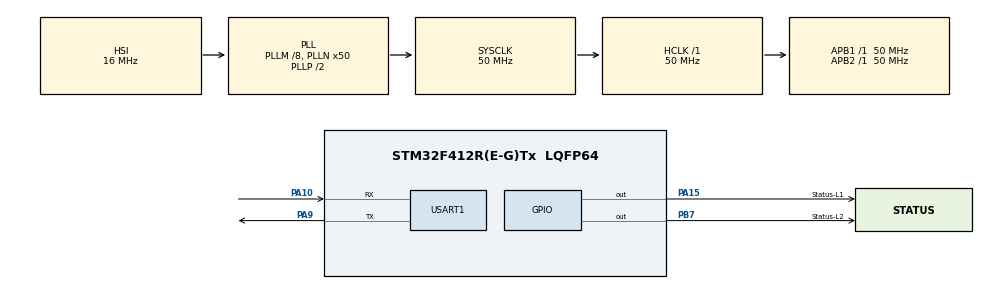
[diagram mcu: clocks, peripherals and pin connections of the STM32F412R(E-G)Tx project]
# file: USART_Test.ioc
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Mcu.Family=STM32F4
Mcu.Name=STM32F412R(E-G)Tx
Mcu.Package=LQFP64
NVIC.PriorityGroup=NVIC_PRIORITYGROUP_4
PA10.Mode=Asynchronous
PA10.Signal=USART1_RX
PA13.Mode=Serial_Wire
PA13.Signal=SYS_JTMS-SWDIO
PA14.Mode=Serial_Wire
PA14.Signal=SYS_JTCK-SWCLK
PA15.GPIO_Label=Status-L1
PA15.Signal=GPIO_Output
PA9.Mode=Asynchronous
PA9.Signal=USART1_TX
PB7.GPIO_Label=Status-L2
PB7.Signal=GPIO_Output
PC14-OSC32_IN.Mode=LSE-External-Oscillator
PC14-OSC32_IN.Signal=RCC_OSC32_IN
PC15-OSC32_OUT.Mode=LSE-External-Oscillator
PC15-OSC32_OUT.Signal=RCC_OSC32_OUT
PH0\ -\ OSC_IN.Mode=HSE-External-Oscillator
PH0\ -\ OSC_IN.Signal=RCC_OSC_IN
PH1\ -\ OSC_OUT.Mode=HSE-External-Oscillator
PH1\ -\ OSC_OUT.Signal=RCC_OSC_OUT
ProjectManager.HeapSize=0x200
ProjectManager.StackSize=0x400
ProjectManager.TargetToolchain=STM32CubeIDE
RCC.AHBFreq_Value=50000000
RCC.APB1Freq_Value=50000000
RCC.APB1TimFreq_Value=50000000
RCC.APB2Freq_Value=50000000
RCC.APB2TimFreq_Value=50000000
RCC.CortexFreq_Value=50000000
RCC.HCLKFreq_Value=50000000
RCC.HSE_VALUE=16000000
RCC.PLLM=8
RCC.PLLN=50
RCC.SYSCLKFreq_VALUE=50000000
RCC.SYSCLKSource=RCC_SYSCLKSOURCE_PLLCLK
RCC.USBFreq_Value=50000000
RCC.VCOOutputFreq_Value=100000000
USART1.VirtualMode=VM_ASYNC
board=custom

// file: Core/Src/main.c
/* USER CODE BEGIN Header */
/**
  ******************************************************************************
  * @file           : main.c
  * @brief          : Main program body
  ******************************************************************************
  * @attention
  *
  * Copyright (c) 2023 STMicroelectronics.
  * All rights reserved.
  *
  * This software is licensed under terms that can be found in the LICENSE file
  * in the root directory of this software component.
  * If no LICENSE file comes with this software, it is provided AS-IS.
  *
  ******************************************************************************
  */
/* USER CODE END Header */
#include "main.h"

UART_HandleTypeDef huart1;

void SystemClock_Config(void);
static void MX_GPIO_Init(void);
static void MX_USART1_UART_Init(void);
/* USER CODE BEGIN PFP */
void testLEDs(void)
{
 	HAL_GPIO_TogglePin(Status_L1_GPIO_Port,Status_L1_Pin);
	HAL_GPIO_TogglePin(Status_L2_GPIO_Port,Status_L2_Pin);
	HAL_Delay(1000);
}
void testUSART(void)
{
	HAL_UART_Transmit(&huart1,"Hello World! Just changed the LED in PF09 Card!!!!!!\n",53,1000);
}
/* USER CODE END PFP */

int main(void)
{

  /* MCU Configuration--------------------------------------------------------*/

  /* Reset of all peripherals, Initializes the Flash interface and the Systick. */
  HAL_Init();

  /* Configure the system clock */
  SystemClock_Config();

  /* Initialize all configured peripherals */
  MX_GPIO_Init();
  MX_USART1_UART_Init();

  /* Infinite loop */
  while (1)
  {
	testLEDs();
	testUSART();
  }
}

void SystemClock_Config(void)
{
  RCC_OscInitTypeDef RCC_OscInitStruct = {0};
  RCC_ClkInitTypeDef RCC_ClkInitStruct = {0};

  /** Configure the main internal regulator output voltage
  */
  __HAL_RCC_PWR_CLK_ENABLE();
  __HAL_PWR_VOLTAGESCALING_CONFIG(PWR_REGULATOR_VOLTAGE_SCALE1);

  /** Initializes the RCC Oscillators according to the specified parameters
  * in the RCC_OscInitTypeDef structure.
  */
  RCC_OscInitStruct.OscillatorType = RCC_OSCILLATORTYPE_HSI;
  RCC_OscInitStruct.HSIState = RCC_HSI_ON;
  RCC_OscInitStruct.HSICalibrationValue = RCC_HSICALIBRATION_DEFAULT;
  RCC_OscInitStruct.PLL.PLLState = RCC_PLL_ON;
  RCC_OscInitStruct.PLL.PLLSource = RCC_PLLSOURCE_HSI;
  RCC_OscInitStruct.PLL.PLLM = 8;
  RCC_OscInitStruct.PLL.PLLN = 50;
  RCC_OscInitStruct.PLL.PLLP = RCC_PLLP_DIV2;
  RCC_OscInitStruct.PLL.PLLQ = 2;
  RCC_OscInitStruct.PLL.PLLR = 2;
  if (HAL_RCC_OscConfig(&RCC_OscInitStruct) != HAL_OK)
  {
    Error_Handler();
  }

  /** Initializes the CPU, AHB and APB buses clocks
  */
  RCC_ClkInitStruct.ClockType = RCC_CLOCKTYPE_HCLK|RCC_CLOCKTYPE_SYSCLK
                              |RCC_CLOCKTYPE_PCLK1|RCC_CLOCKTYPE_PCLK2;
  RCC_ClkInitStruct.SYSCLKSource = RCC_SYSCLKSOURCE_PLLCLK;
  RCC_ClkInitStruct.AHBCLKDivider = RCC_SYSCLK_DIV1;
  RCC_ClkInitStruct.APB1CLKDivider = RCC_HCLK_DIV1;
  RCC_ClkInitStruct.APB2CLKDivider = RCC_HCLK_DIV1;

  if (HAL_RCC_ClockConfig(&RCC_ClkInitStruct, FLASH_LATENCY_1) != HAL_OK)
  {
    Error_Handler();
  }
}

static void MX_USART1_UART_Init(void)
{

  huart1.Instance = USART1;
  huart1.Init.BaudRate = 115200;
  huart1.Init.WordLength = UART_WORDLENGTH_8B;
  huart1.Init.StopBits = UART_STOPBITS_1;
  huart1.Init.Parity = UART_PARITY_NONE;
  huart1.Init.Mode = UART_MODE_TX_RX;
  huart1.Init.HwFlowCtl = UART_HWCONTROL_NONE;
  huart1.Init.OverSampling = UART_OVERSAMPLING_16;
  if (HAL_UART_Init(&huart1) != HAL_OK)
  {
    Error_Handler();
  }

}

static void MX_GPIO_Init(void)
{
  GPIO_InitTypeDef GPIO_InitStruct = {0};

  /* GPIO Ports Clock Enable */
  __HAL_RCC_GPIOC_CLK_ENABLE();
  __HAL_RCC_GPIOH_CLK_ENABLE();
  __HAL_RCC_GPIOA_CLK_ENABLE();
  __HAL_RCC_GPIOB_CLK_ENABLE();

  /*Configure GPIO pin Output Level */
  HAL_GPIO_WritePin(Status_L1_GPIO_Port, Status_L1_Pin, GPIO_PIN_RESET);

  /*Configure GPIO pin Output Level */
  HAL_GPIO_WritePin(Status_L2_GPIO_Port, Status_L2_Pin, GPIO_PIN_RESET);

  /*Configure GPIO pin : Status_L1_Pin */
  GPIO_InitStruct.Pin = Status_L1_Pin;
  GPIO_InitStruct.Mode = GPIO_MODE_OUTPUT_PP;
  GPIO_InitStruct.Pull = GPIO_NOPULL;
  GPIO_InitStruct.Speed = GPIO_SPEED_FREQ_LOW;
  HAL_GPIO_Init(Status_L1_GPIO_Port, &GPIO_InitStruct);

  /*Configure GPIO pin : Status_L2_Pin */
  GPIO_InitStruct.Pin = Status_L2_Pin;
  GPIO_InitStruct.Mode = GPIO_MODE_OUTPUT_PP;
  GPIO_InitStruct.Pull = GPIO_NOPULL;
  GPIO_InitStruct.Speed = GPIO_SPEED_FREQ_LOW;
  HAL_GPIO_Init(Status_L2_GPIO_Port, &GPIO_InitStruct);

}

void Error_Handler(void)
{
  __disable_irq();
  while (1)
  {
  }
}
